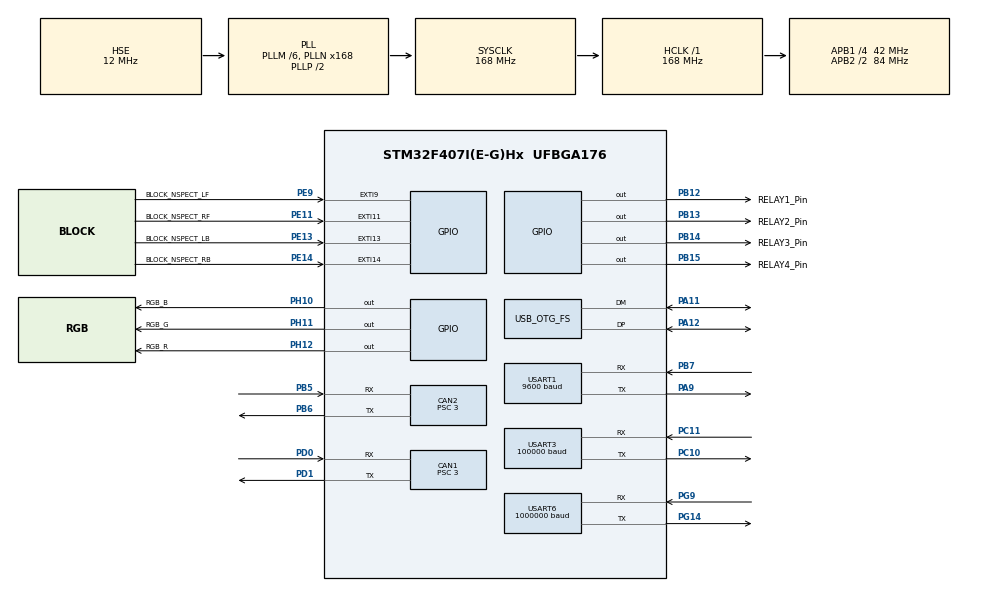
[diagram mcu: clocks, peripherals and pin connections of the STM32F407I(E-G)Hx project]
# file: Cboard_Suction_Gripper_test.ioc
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CAN1.BS1=CAN_BS1_10TQ
CAN1.BS2=CAN_BS2_3TQ
CAN1.CalculateBaudRate=1000000
CAN1.CalculateTimeBit=1000
CAN1.CalculateTimeQuantum=71.42857142857143
CAN1.Prescaler=3
CAN2.BS1=CAN_BS1_10TQ
CAN2.BS2=CAN_BS2_3TQ
CAN2.CalculateBaudRate=1000000
CAN2.CalculateTimeBit=1000
CAN2.CalculateTimeQuantum=71.42857142857143
CAN2.Prescaler=3
Dma.Request0=USART3_RX
Dma.Request1=USART6_TX
Dma.Request2=USART1_TX
Dma.USART1_TX.2.Direction=DMA_MEMORY_TO_PERIPH
Dma.USART1_TX.2.FIFOMode=DMA_FIFOMODE_DISABLE
Dma.USART1_TX.2.Instance=DMA2_Stream7
Dma.USART1_TX.2.MemDataAlignment=DMA_MDATAALIGN_BYTE
Dma.USART1_TX.2.MemInc=DMA_MINC_ENABLE
Dma.USART1_TX.2.Mode=DMA_NORMAL
Dma.USART1_TX.2.PeriphDataAlignment=DMA_PDATAALIGN_BYTE
Dma.USART1_TX.2.PeriphInc=DMA_PINC_DISABLE
Dma.USART1_TX.2.Priority=DMA_PRIORITY_HIGH
Dma.USART3_RX.0.Direction=DMA_PERIPH_TO_MEMORY
Dma.USART3_RX.0.FIFOMode=DMA_FIFOMODE_DISABLE
Dma.USART3_RX.0.Instance=DMA1_Stream1
Dma.USART3_RX.0.MemDataAlignment=DMA_MDATAALIGN_BYTE
Dma.USART3_RX.0.MemInc=DMA_MINC_ENABLE
Dma.USART3_RX.0.Mode=DMA_NORMAL
Dma.USART3_RX.0.PeriphDataAlignment=DMA_PDATAALIGN_BYTE
Dma.USART3_RX.0.PeriphInc=DMA_PINC_DISABLE
Dma.USART3_RX.0.Priority=DMA_PRIORITY_VERY_HIGH
Dma.USART6_TX.1.Direction=DMA_MEMORY_TO_PERIPH
Dma.USART6_TX.1.FIFOMode=DMA_FIFOMODE_DISABLE
Dma.USART6_TX.1.Instance=DMA2_Stream6
Dma.USART6_TX.1.MemDataAlignment=DMA_MDATAALIGN_BYTE
Dma.USART6_TX.1.MemInc=DMA_MINC_ENABLE
Dma.USART6_TX.1.Mode=DMA_NORMAL
Dma.USART6_TX.1.PeriphDataAlignment=DMA_PDATAALIGN_BYTE
Dma.USART6_TX.1.PeriphInc=DMA_PINC_DISABLE
Dma.USART6_TX.1.Priority=DMA_PRIORITY_HIGH
FREERTOS.Tasks01=defaultTask,1,128,StartDefaultTask,As weak,NULL,Dynamic,NULL,NULL;RobotArm_TASK,1,1024,arm_control_task,As weak,NULL,Dynamic,NULL,NULL;LED_TASK,-1,256,led_indicate_task,As weak,NULL,Dynamic,NULL,NULL;Pump_control,1,512,pump_control_task,As weak,NULL,Dynamic,NULL,NULL;debug_TASK,1,256,usartr_debug_task,As weak,NULL,Dynamic,NULL,NULL;data_update_TAS,1,256,update_task,As weak,NULL,Dynamic,NULL,NULL;gimbal_Task,0,256,gimbal_control_task,As weak,NULL,Dynamic,NULL,NULL
Mcu.Family=STM32F4
Mcu.Name=STM32F407I(E-G)Hx
Mcu.Package=UFBGA176
NVIC.CAN1_RX0_IRQn=true\:6\:0\:true\:false\:true\:true\:true\:true\:true
NVIC.DMA1_Stream1_IRQn=true\:5\:0\:false\:false\:true\:true\:false\:true\:true
NVIC.DMA2_Stream6_IRQn=true\:5\:0\:false\:false\:true\:true\:false\:true\:true
NVIC.DMA2_Stream7_IRQn=true\:5\:0\:false\:false\:true\:true\:false\:true\:true
NVIC.OTG_FS_IRQn=true\:5\:0\:false\:false\:true\:true\:false\:true\:true
NVIC.PriorityGroup=NVIC_PRIORITYGROUP_4
NVIC.TIM4_IRQn=true\:15\:0\:false\:false\:true\:false\:false\:true\:true
NVIC.TimeBase=TIM4_IRQn
NVIC.TimeBaseIP=TIM4
NVIC.USART1_IRQn=true\:5\:0\:false\:false\:true\:true\:true\:true\:true
NVIC.USART3_IRQn=true\:4\:0\:true\:false\:false\:false\:true\:true\:true
NVIC.USART6_IRQn=true\:5\:0\:false\:false\:true\:true\:true\:true\:true
PA11.Mode=Device_Only
PA11.Signal=USB_OTG_FS_DM
PA12.Mode=Device_Only
PA12.Signal=USB_OTG_FS_DP
PA9.Mode=Asynchronous
PA9.Signal=USART1_TX
PB12.GPIO_Label=RELAY1_Pin
PB12.GPIO_PuPd=GPIO_PULLDOWN
PB12.GPIO_Speed=GPIO_SPEED_FREQ_MEDIUM
PB12.Signal=GPIO_Output
PB13.GPIO_Label=RELAY2_Pin
PB13.GPIO_PuPd=GPIO_PULLDOWN
PB13.GPIO_Speed=GPIO_SPEED_FREQ_MEDIUM
PB13.Signal=GPIO_Output
PB14.GPIO_Label=RELAY3_Pin
PB14.GPIO_PuPd=GPIO_PULLDOWN
PB14.GPIO_Speed=GPIO_SPEED_FREQ_MEDIUM
PB14.Signal=GPIO_Output
PB15.GPIO_Label=RELAY4_Pin
PB15.GPIO_PuPd=GPIO_PULLDOWN
PB15.GPIO_Speed=GPIO_SPEED_FREQ_MEDIUM
PB15.Signal=GPIO_Output
PB5.Mode=CAN_Activate
PB5.Signal=CAN2_RX
PB6.Mode=CAN_Activate
PB6.Signal=CAN2_TX
PB7.Mode=Asynchronous
PB7.Signal=USART1_RX
PC10.Mode=Asynchronous
PC10.Signal=USART3_TX
PC11.Mode=Asynchronous
PC11.Signal=USART3_RX
PD0.Mode=CAN_Activate
PD0.Signal=CAN1_RX
PD1.Mode=CAN_Activate
PD1.Signal=CAN1_TX
PE11.GPIO_Label=BLOCK_NSPECT_RF
PE11.GPIO_ModeDefaultEXTI=GPIO_MODE_IT_RISING_FALLING
PE11.GPIO_PuPd=GPIO_PULLUP
PE11.Signal=GPXTI11
PE13.GPIO_Label=BLOCK_NSPECT_LB
PE13.GPIO_ModeDefaultEXTI=GPIO_MODE_IT_RISING_FALLING
PE13.GPIO_PuPd=GPIO_PULLUP
PE13.Signal=GPXTI13
PE14.GPIO_Label=BLOCK_NSPECT_RB
PE14.GPIO_ModeDefaultEXTI=GPIO_MODE_IT_RISING_FALLING
PE14.GPIO_PuPd=GPIO_PULLUP
PE14.Signal=GPXTI14
PE9.GPIO_Label=BLOCK_NSPECT_LF
PE9.GPIO_ModeDefaultEXTI=GPIO_MODE_IT_RISING_FALLING
PE9.GPIO_PuPd=GPIO_PULLUP
PE9.Signal=GPXTI9
PG14.Mode=Asynchronous
PG14.Signal=USART6_TX
PG9.Mode=Asynchronous
PG9.Signal=USART6_RX
PH0-OSC_IN.Mode=HSE-External-Oscillator
PH0-OSC_IN.Signal=RCC_OSC_IN
PH1-OSC_OUT.Mode=HSE-External-Oscillator
PH1-OSC_OUT.Signal=RCC_OSC_OUT
PH10.GPIO_Label=RGB_B
PH10.Signal=GPIO_Output
PH11.GPIO_Label=RGB_G
PH11.Signal=GPIO_Output
PH12.GPIO_Label=RGB_R
PH12.Signal=GPIO_Output
ProjectManager.HeapSize=0x800
ProjectManager.StackSize=0x1000
ProjectManager.TargetToolchain=CMake
RCC.48MHZClocksFreq_Value=48000000
RCC.AHBFreq_Value=168000000
RCC.APB1CLKDivider=RCC_HCLK_DIV4
RCC.APB1Freq_Value=42000000
RCC.APB1TimFreq_Value=84000000
RCC.APB2CLKDivider=RCC_HCLK_DIV2
RCC.APB2Freq_Value=84000000
RCC.APB2TimFreq_Value=168000000
RCC.CortexFreq_Value=168000000
RCC.HCLKFreq_Value=168000000
RCC.HSE_VALUE=12000000
RCC.HSI_VALUE=16000000
RCC.LSE_VALUE=32768
RCC.PLLM=6
RCC.PLLN=168
RCC.PLLQ=7
RCC.SYSCLKFreq_VALUE=168000000
RCC.SYSCLKSource=RCC_SYSCLKSOURCE_PLLCLK
RCC.VCOOutputFreq_Value=336000000
USART1.BaudRate=9600
USART1.VirtualMode=VM_ASYNC
USART3.BaudRate=100000
USART3.VirtualMode=VM_ASYNC
USART6.BaudRate=1000000
USART6.VirtualMode=VM_ASYNC
USB_DEVICE.CLASS_NAME_FS=CDC
USB_DEVICE.VirtualMode-CDC_FS=Cdc
USB_DEVICE.VirtualModeFS=Cdc_FS
USB_OTG_FS.VirtualMode=Device_Only
VP_FREERTOS_VS_CMSIS_V1.Mode=CMSIS_V1
VP_SYS_VS_tim4.Mode=TIM4
VP_USB_DEVICE_VS_USB_DEVICE_CDC_FS.Mode=CDC_FS
board=custom

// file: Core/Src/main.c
/* USER CODE BEGIN Header */
/**
  ******************************************************************************
  * @file           : main.c
  * @brief          : Main program body
  ******************************************************************************
  * @attention
  *
  * Copyright (c) 2025 STMicroelectronics.
  * All rights reserved.
  *
  * This software is licensed under terms that can be found in the LICENSE file
  * in the root directory of this software component.
  * If no LICENSE file comes with this software, it is provided AS-IS.
  *
  ******************************************************************************
  */
/* USER CODE END Header */
#include "main.h"
#include "cmsis_os.h"
#include "can.h"
#include "dma.h"
#include "usart.h"
#include "usb_device.h"
#include "gpio.h"

/* USER CODE BEGIN Includes */
#include "bsp_can.h"
#include "bsp_usart.h"
/* USER CODE END Includes */

void SystemClock_Config(void);
void MX_FREERTOS_Init(void);

int main(void)
{

  /* MCU Configuration--------------------------------------------------------*/

  /* Reset of all peripherals, Initializes the Flash interface and the Systick. */
    HAL_Init();

  /* Configure the system clock */
  SystemClock_Config();

  /* Initialize all configured peripherals */
  MX_GPIO_Init();
  MX_DMA_Init();
  MX_CAN1_Init();
  MX_USART1_UART_Init();
  MX_CAN2_Init();
  MX_USART6_UART_Init();
  MX_USART3_UART_Init();
  /* USER CODE BEGIN 2 */
  can_filter_init();
  usart1_tx_dma_init();
  //remote_control_init();
  /* USER CODE END 2 */

  /* Call init function for freertos objects (in cmsis_os2.c) */
  MX_FREERTOS_Init();

  /* Start scheduler */
  osKernelStart();

  /* We should never get here as control is now taken by the scheduler */

  /* Infinite loop */
  while (1)
  {

  }
}

void SystemClock_Config(void)
{
  RCC_OscInitTypeDef RCC_OscInitStruct = {0};
  RCC_ClkInitTypeDef RCC_ClkInitStruct = {0};

  /** Configure the main internal regulator output voltage
  */
  __HAL_RCC_PWR_CLK_ENABLE();
  __HAL_PWR_VOLTAGESCALING_CONFIG(PWR_REGULATOR_VOLTAGE_SCALE1);

  /** Initializes the RCC Oscillators according to the specified parameters
  * in the RCC_OscInitTypeDef structure.
  */
  RCC_OscInitStruct.OscillatorType = RCC_OSCILLATORTYPE_HSE;
  RCC_OscInitStruct.HSEState = RCC_HSE_ON;
  RCC_OscInitStruct.PLL.PLLState = RCC_PLL_ON;
  RCC_OscInitStruct.PLL.PLLSource = RCC_PLLSOURCE_HSE;
  RCC_OscInitStruct.PLL.PLLM = 6;
  RCC_OscInitStruct.PLL.PLLN = 168;
  RCC_OscInitStruct.PLL.PLLP = RCC_PLLP_DIV2;
  RCC_OscInitStruct.PLL.PLLQ = 7;
  if (HAL_RCC_OscConfig(&RCC_OscInitStruct) != HAL_OK)
  {
    Error_Handler();
  }

  /** Initializes the CPU, AHB and APB buses clocks
  */
  RCC_ClkInitStruct.ClockType = RCC_CLOCKTYPE_HCLK|RCC_CLOCKTYPE_SYSCLK
                              |RCC_CLOCKTYPE_PCLK1|RCC_CLOCKTYPE_PCLK2;
  RCC_ClkInitStruct.SYSCLKSource = RCC_SYSCLKSOURCE_PLLCLK;
  RCC_ClkInitStruct.AHBCLKDivider = RCC_SYSCLK_DIV1;
  RCC_ClkInitStruct.APB1CLKDivider = RCC_HCLK_DIV4;
  RCC_ClkInitStruct.APB2CLKDivider = RCC_HCLK_DIV2;

  if (HAL_RCC_ClockConfig(&RCC_ClkInitStruct, FLASH_LATENCY_5) != HAL_OK)
  {
    Error_Handler();
  }
}

void HAL_TIM_PeriodElapsedCallback(TIM_HandleTypeDef *htim)
{
  if (htim->Instance == TIM4)
  {
    HAL_IncTick();
  }
}

void Error_Handler(void)
{
  __disable_irq();
  while (1)
  {
  }
}

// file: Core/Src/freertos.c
/* USER CODE BEGIN Header */
/**
  ******************************************************************************
  * File Name          : freertos.c
  * Description        : Code for freertos applications
  ******************************************************************************
  * @attention
  *
  * Copyright (c) 2025 STMicroelectronics.
  * All rights reserved.
  *
  * This software is licensed under terms that can be found in the LICENSE file
  * in the root directory of this software component.
  * If no LICENSE file comes with this software, it is provided AS-IS.
  *
  ******************************************************************************
  */
/* USER CODE END Header */

#include "FreeRTOS.h"
#include "task.h"
#include "main.h"
#include "cmsis_os.h"

osThreadId defaultTaskHandle;
osThreadId RobotArm_TASKHandle;
osThreadId LED_TASKHandle;
osThreadId Pump_controlHandle;
osThreadId debug_TASKHandle;
osThreadId data_update_TASHandle;
osThreadId gimbal_TaskHandle;

void StartDefaultTask(void const * argument);
void arm_control_task(void const * argument);
void led_indicate_task(void const * argument);
void pump_control_task(void const * argument);
void usartr_debug_task(void const * argument);
void update_task(void const * argument);
void gimbal_control_task(void const * argument);

extern void MX_USB_DEVICE_Init(void);
void MX_FREERTOS_Init(void); /* (MISRA C 2004 rule 8.1) */

/* GetIdleTaskMemory prototype (linked to static allocation support) */
void vApplicationGetIdleTaskMemory( StaticTask_t **ppxIdleTaskTCBBuffer, StackType_t **ppxIdleTaskStackBuffer, uint32_t *pulIdleTaskStackSize );

/* USER CODE BEGIN GET_IDLE_TASK_MEMORY */
static StaticTask_t xIdleTaskTCBBuffer;
static StackType_t xIdleStack[configMINIMAL_STACK_SIZE];

void vApplicationGetIdleTaskMemory( StaticTask_t **ppxIdleTaskTCBBuffer, StackType_t **ppxIdleTaskStackBuffer, uint32_t *pulIdleTaskStackSize )
{
  *ppxIdleTaskTCBBuffer = &xIdleTaskTCBBuffer;
  *ppxIdleTaskStackBuffer = &xIdleStack[0];
  *pulIdleTaskStackSize = configMINIMAL_STACK_SIZE;
  /* place for user code */
}
/* USER CODE END GET_IDLE_TASK_MEMORY */

void MX_FREERTOS_Init(void) {

  /* Create the thread(s) */
  /* definition and creation of defaultTask */
  osThreadDef(defaultTask, StartDefaultTask, osPriorityAboveNormal, 0, 128);
  defaultTaskHandle = osThreadCreate(osThread(defaultTask), NULL);

  /* definition and creation of RobotArm_TASK */
  osThreadDef(RobotArm_TASK, arm_control_task, osPriorityAboveNormal, 0, 1024);
  RobotArm_TASKHandle = osThreadCreate(osThread(RobotArm_TASK), NULL);

  /* definition and creation of LED_TASK */
  osThreadDef(LED_TASK, led_indicate_task, osPriorityBelowNormal, 0, 256);
  LED_TASKHandle = osThreadCreate(osThread(LED_TASK), NULL);

  /* definition and creation of Pump_control */
  osThreadDef(Pump_control, pump_control_task, osPriorityAboveNormal, 0, 512);
  Pump_controlHandle = osThreadCreate(osThread(Pump_control), NULL);

  /* definition and creation of debug_TASK */
  osThreadDef(debug_TASK, usartr_debug_task, osPriorityAboveNormal, 0, 256);
  debug_TASKHandle = osThreadCreate(osThread(debug_TASK), NULL);

  /* definition and creation of data_update_TAS */
  osThreadDef(data_update_TAS, update_task, osPriorityAboveNormal, 0, 256);
  data_update_TASHandle = osThreadCreate(osThread(data_update_TAS), NULL);

  /* definition and creation of gimbal_Task */
  osThreadDef(gimbal_Task, gimbal_control_task, osPriorityNormal, 0, 256);
  gimbal_TaskHandle = osThreadCreate(osThread(gimbal_Task), NULL);

}

__weak void StartDefaultTask(void const * argument)
{
  /* init code for USB_DEVICE */
  MX_USB_DEVICE_Init();
  for(;;)
  {
    osDelay(1);
  }
}

__weak void arm_control_task(void const * argument)
{
  for(;;)
  {
    osDelay(1);
  }
}

__weak void led_indicate_task(void const * argument)
{
  for(;;)
  {
    osDelay(1);
  }
}

__weak void pump_control_task(void const * argument)
{
  for(;;)
  {
    osDelay(1);
  }
}

__weak void usartr_debug_task(void const * argument)
{
  for(;;)
  {
    osDelay(1);
  }
}

__weak void update_task(void const * argument)
{
  for(;;)
  {
    osDelay(1);
  }
}

__weak void gimbal_control_task(void const * argument)
{
  for(;;)
  {
    osDelay(1);
  }
}
